# MKW41Z4 register map
Vendor: Freescale Semiconductor, Inc.; Series: Kinetis_W; File version: 1.6
CPU: CM0PLUS r0p0, little endian, no MPU, no FPU, VTOR, 2 interrupt priority bits
Registers are 16-bit, read-write, no defined reset value unless marked. A register's access mark holds for its fields unless they carry their own. Offsets are from the block's base; [hi:lo] are bit positions; {n}, {i} and the like mark numbered series.

## XCVR_PKT_RAM
Base 0x4005C700
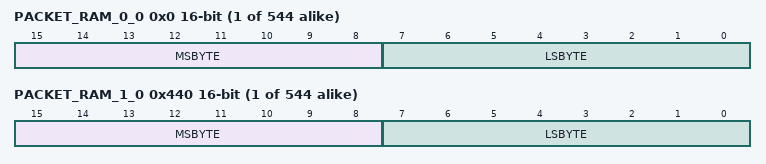
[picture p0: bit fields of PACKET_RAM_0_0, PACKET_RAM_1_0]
{0x0+2i} PACKET_RAM_0_{i} (i=0..543) — Shared Packet RAM for multiple Link Layer usage.
  [15:8] MSBYTE, [7:0] LSBYTE
{0x440+2i} PACKET_RAM_1_{i} (i=0..543) — Shared Packet RAM for multiple Link Layer usage.
  [15:8] MSBYTE, [7:0] LSBYTE

## CMT — Carrier Modulator Transmitter
Base 0x40062000; register names take the prefix CMT_
0x00 CGH1 8-bit — CMT Carrier Generator High Data Register 1
  [7:0] PH — Primary Carrier High Time Data Value
0x01 CGL1 8-bit — CMT Carrier Generator Low Data Register 1
  [7:0] PL — Primary Carrier Low Time Data Value
0x02 CGH2 8-bit — CMT Carrier Generator High Data Register 2
  [7:0] SH — Secondary Carrier High Time Data Value
0x03 CGL2 8-bit — CMT Carrier Generator Low Data Register 2
  [7:0] SL — Secondary Carrier Low Time Data Value
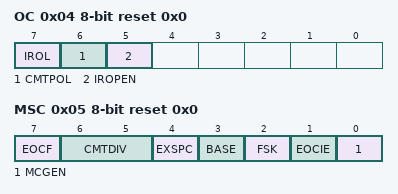
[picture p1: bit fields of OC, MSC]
0x04 OC 8-bit reset 0x0 — CMT Output Control Register
  [7] IROL — IRO Latch Control
  [6] CMTPOL — CMT Output Polarity
    0=The IRO signal is active-low; 1=The IRO signal is active-high
  [5] IROPEN — IRO Pin Enable
    0=The IRO signal is disabled; 1=The IRO signal is enabled as output
0x05 MSC 8-bit reset 0x0 — CMT Modulator Status and Control Register
  [7] EOCF ro — End Of Cycle Status Flag
    0=End of modulation cycle has not occured since the flag last cleared; 1=End of modulator cycle has occurred
  [6:5] CMTDIV — CMT Clock Divide Prescaler
    0=IF * 1; 1=IF * 2; 2=IF * 4; 3=IF * 8
  [4] EXSPC — Extended Space Enable
    0=Extended space is disabled; 1=Extended space is enabled
  [3] BASE — Baseband Enable
    0=Baseband mode is disabled; 1=Baseband mode is enabled
  [2] FSK — FSK Mode Select
    0=The CMT operates in Time or Baseband mode; 1=The CMT operates in FSK mode
  [1] EOCIE — End of Cycle Interrupt Enable
    0=CPU interrupt is disabled; 1=CPU interrupt is enabled
  [0] MCGEN — Modulator and Carrier Generator Enable
    0=Modulator and carrier generator disabled; 1=Modulator and carrier generator enabled
0x06 CMD1 8-bit — CMT Modulator Data Register Mark High
  [7:0] MB — MB[15:8]
0x07 CMD2 8-bit — CMT Modulator Data Register Mark Low
  [7:0] MB — MB[7:0]
0x08 CMD3 8-bit — CMT Modulator Data Register Space High
  [7:0] SB — SB[15:8]
0x09 CMD4 8-bit — CMT Modulator Data Register Space Low
  [7:0] SB — SB[7:0]
0x0A PPS 8-bit reset 0x0 — CMT Primary Prescaler Register
  [3:0] PPSDIV — Primary Prescaler Divider
    {v}=Bus clock * {v+1} (v=0..15)
0x0B DMA 8-bit reset 0x0 — CMT Direct Memory Access Register
  [0] DMA — DMA Enable
    0=DMA transfer request and done are disabled; 1=DMA transfer request and done are enabled

## CMP0 — High-Speed Comparator (CMP), Voltage Reference (VREF) Digital-to-Analog Converter (DAC), and Analog Mux (ANMUX)
Base 0x40073000; register names take the prefix CMP0_
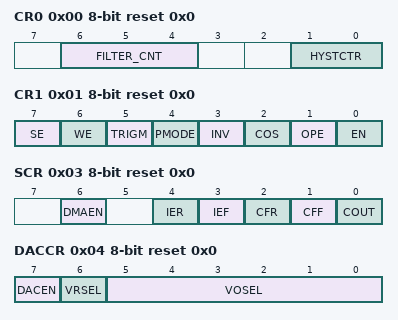
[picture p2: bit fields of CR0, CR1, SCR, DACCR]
0x00 CR0 8-bit reset 0x0 — CMP Control Register 0
  [6:4] FILTER_CNT — Filter Sample Count
    0=Filter is disabled. SE = 0, COUT = COUTA.; 1=One sample must agree. The comparator output is simply sampled.; {v}={v} consecutive samples must agree (v=2..7)
  [1:0] HYSTCTR — Comparator hard block hysteresis control
    {v}=Level {v} (v=0..3)
0x01 CR1 8-bit reset 0x0 — CMP Control Register 1
  [7] SE — Sample Enable
    0=Sampling mode is not selected; 1=Sampling mode is selected
  [6] WE — Windowing Enable
    0=Windowing mode is not selected; 1=Windowing mode is selected
  [5] TRIGM — Trigger Mode Enable
    0=Trigger mode is disabled; 1=Trigger mode is enabled
  [4] PMODE — Power Mode Select
    0=Low-Speed (LS) Comparison mode selected. In this mode, CMP has slower output propagation delay and lower current consumption.; 1=High-Speed (HS) Comparison mode selected. In this mode, CMP has faster output propagation delay and higher current consumption.
  [3] INV — Comparator INVERT
    0=Does not invert the comparator output; 1=Inverts the comparator output
  [2] COS — Comparator Output Select
    0=Set the filtered comparator output (CMPO) to equal COUT; 1=Set the unfiltered comparator output (CMPO) to equal COUTA
  [1] OPE — Comparator Output Pin Enable
    0=CMPO is not available on the associated CMPO output pin. If the comparator does not own the pin, this field has no effect.; 1=CMPO is available on the associated CMPO output pin. The comparator output (CMPO) is driven out on the associated CMPO output pin if the comparator owns the pin. If the comparator does not own the field, this bit has no effect.
  [0] EN — Comparator Module Enable
    0=Analog Comparator is disabled; 1=Analog Comparator is enabled
0x02 FPR 8-bit reset 0x0 — CMP Filter Period Register
  [7:0] FILT_PER — Filter Sample Period
0x03 SCR 8-bit reset 0x0 — CMP Status and Control Register
  [6] DMAEN — DMA Enable Control
    0=DMA is disabled; 1=DMA is enabled
  [4] IER — Comparator Interrupt Enable Rising
    0=Interrupt is disabled; 1=Interrupt is enabled
  [3] IEF — Comparator Interrupt Enable Falling
    0=Interrupt is disabled; 1=Interrupt is enabled
  [2] CFR — Analog Comparator Flag Rising
    0=Rising-edge on COUT has not been detected; 1=Rising-edge on COUT has occurred
  [1] CFF — Analog Comparator Flag Falling
    0=Falling-edge on COUT has not been detected; 1=Falling-edge on COUT has occurred
  [0] COUT ro — Analog Comparator Output
0x04 DACCR 8-bit reset 0x0 — DAC Control Register
  [7] DACEN — DAC Enable
    0=DAC is disabled; 1=DAC is enabled
  [6] VRSEL — Supply Voltage Reference Source Select
    0=Vin1 is selected as resistor ladder network supply reference; 1=Vin2 is selected as resistor ladder network supply reference
  [5:0] VOSEL — DAC Output Voltage Select
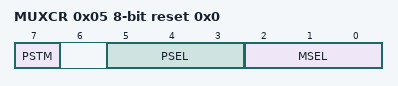
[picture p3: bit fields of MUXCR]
0x05 MUXCR 8-bit reset 0x0 — MUX Control Register
  [7] PSTM — Pass Through Mode Enable
    0=Pass Through Mode is disabled; 1=Pass Through Mode is enabled
  [5:3] PSEL — Plus Input Mux Control
    {v}=IN{v} (v=0..7)
  [2:0] MSEL — Minus Input Mux Control
    {v}=IN{v} (v=0..7)
